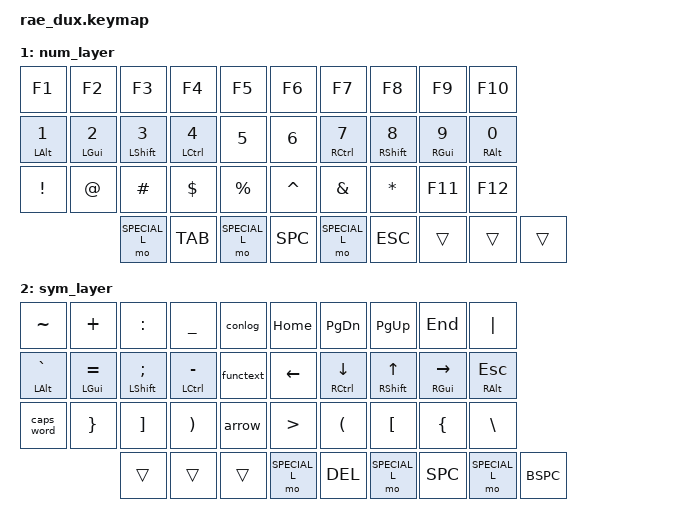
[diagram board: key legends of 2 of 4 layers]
/*
 * Copyright (c) 2021 The ZMK Contributors
 *
 * SPDX-License-Identifier: MIT
 */

#include <behaviors.dtsi>
#include <dt-bindings/zmk/bt.h>
#include <dt-bindings/zmk/keys.h>

&caps_word {
    continue-list = <UNDERSCORE MINUS BSPC>;
};

#define BASE_L  0
#define NUM_L   1
#define SYM_L   2
#define SPECIAL_L   3

&lt {
    quick-tap-ms = <200>;
};

/ {
    macros {
        ZMK_MACRO(promise, wait-ms = <30>; tap-ms = <30>; bindings = <&kp DOT &kp T &kp H &kp E &kp N &kp LPAR &kp X &kp SPC &kp EQUAL &kp GT &kp SPC &kp LBRC &kp RBRC &kp RPAR>;)
        ZMK_MACRO(anon, wait-ms = <30>; tap-ms = <30>; bindings = <&kp LPAR &kp RPAR &kp SPC &kp EQUAL &kp GT &kp SPC &kp LBRC &kp RBRC>;)
        ZMK_MACRO(arrow, wait-ms = <30>; tap-ms = <30>; bindings = <&kp EQUAL &kp GT>;)
        ZMK_MACRO(functext, wait-ms = <30>; tap-ms = <30>; bindings = <&kp F &kp U &kp N &kp C &kp T &kp I &kp O &kp N>;)
        ZMK_MACRO(conlog, wait-ms = <30>; tap-ms = <30>; bindings = <&kp C &kp O &kp N &kp S &kp O &kp L &kp E &kp DOT &kp L &kp O &kp G &kp LPAR>;)
    };

    combos {
        compatible = "zmk,combos";

        #define COMBO(NAME, BINDINGS, KEYPOS, TIMEOUT) \
              combo_##NAME { \
                timeout-ms = <TIMEOUT>; \
                bindings = <BINDINGS>; \
                key-positions = <KEYPOS>; \
              };

        /*                KEY POSITIONS

          ╭────────────────────╮ ╭────────────────────╮
          │  0   1   2   3   4 │ │  5   6   7   8   9 │
          │ 10  11  12  13  14 │ │ 15  16  17  18  19 │
          │ 20  21  22  23  24 │ │ 25  26  27  28  29 │
          ╰───────╮ 30  31  32 │ │ 33  34  35 ╭───────╯
                  ╰────────────╯ ╰────────────╯        */
        
        COMBO(caps_word_left, &caps_word, 13 14, 60)
    };

    behaviors {
        lhm: left_hand_positional_hold_tap {
            compatible = "zmk,behavior-hold-tap";
            label = "LEFT_POSITIONAL_HOLD_TAP";
            #binding-cells = <2>;
            flavor = "tap-preferred";
            tapping-term-ms = <200>;
            quick-tap-ms = <200>;
            // global-quick-tap-ms = <100>;
            bindings = <&kp>, <&kp>;
            // hold-trigger-key-positions = <5 6 7 8 9 15 16 17 18 19 25 26 27 28 29 30 31 32 33 34 35>;
            hold-trigger-key-positions = <5 6 7 8 9 10 11 12 13 15 16 17 18 19 25 26 27 28 29 30 31 32 33 34 35>;
        };

        lhctrl: left_special_hand_positional_hold_tap {
            compatible = "zmk,behavior-hold-tap";
            label = "LEFT_POSITIONAL_HOLD_TAP";
            #binding-cells = <2>;
            flavor = "tap-preferred";
            tapping-term-ms = <200>;
            quick-tap-ms = <200>;
            // global-quick-tap-ms = <100>;
            bindings = <&kp>, <&kp>;
            // hold-trigger-key-positions = <5 6 7 8 9 15 16 17 18 19 25 26 27 28 29 30 31 32 33 34 35>;
            hold-trigger-key-positions = <1 5 6 7 8 9 10 11 12 13 15 16 17 18 19 20 21 22 24 25 26 27 28 29 30 31 32 33 34 35>;
        };

        rhm: right_hand_positional_hold_tap {
            compatible = "zmk,behavior-hold-tap";
            label = "RIGHT_POSITIONAL_HOLD_TAP";
            #binding-cells = <2>;
            flavor = "tap-preferred";
            tapping-term-ms = <200>;
            quick-tap-ms = <200>;
            // global-quick-tap-ms = <100>;
            bindings = <&kp>, <&kp>;
            // hold-trigger-key-positions = <0 1 2 3 4 10 11 12 13 14 20 21 22 23 24 30 31 32 33 34 35>;
            hold-trigger-key-positions = <0 1 2 3 4 10 11 12 13 14 16 17 18 19 20 21 22 23 24 30 31 32 33 34 35>;
        };

        // base_lt: base_layer_hold_tap {
        //     compatible = "zmk,behavior-hold-tap";
        //     label = "BASE_LAYER_HOLD_TAP";
        //     #binding-cells = <2>;
        //     flavor = "tap-preferred";
        //     tapping-term-ms = <200>;
        //     quick-tap-ms = <200>;
        //     // global-quick-tap-ms = <100>;
        //     bindings = <&mo>, <&kp>;
        // };
    };

	keymap {
		compatible = "zmk,keymap";

		base_layer {
			bindings = <
                   &kp Q         &kp W         &kp F              &kp P              &kp B                &kp J              &kp L                &kp U                 &kp Y         &kp APOS
                   &lhm LALT A   &lhm LGUI R   &lhm LSHFT S       &lhctrl LCTRL T    &kp G                &kp K              &rhm LCTRL N         &rhm RSHFT E          &rhm LGUI I   &rhm RALT O
                   &kp Z         &kp X         &kp C              &kp D              &kp V                &kp M              &kp H                &kp COMMA             &kp DOT       &kp FSLH
			    	 /*&            &*/           &mo SYM_L TAB    &mo SYM_L SPC       &mo SPECIAL_L ESC      &mo SPECIAL_L DEL   &mo NUM_L RET   &mo NUM_L BSPC
			>;
		};

		num_layer {
			bindings = <
                   &kp F1           &kp F2          &kp F3          &kp F4          &kp F5              &kp F6      &kp F7          &kp F8          &kp F9          &kp F10
                   &lhm LALT N1     &lhm LGUI N2    &lhm LSHFT N3   &lhm LCTRL N4   &kp N5              &kp N6      &rhm RCTRL N7   &rhm RSHFT N8   &rhm RGUI N9    &rhm RALT N0
                   &kp EXCL         &kp AT          &kp HASH        &kp DLLR        &kp PRCNT           &kp CARET   &kp AMPS        &kp STAR        &kp F11         &kp F12
				 /*&            &*/                 &mo SPECIAL_L TAB    &mo SPECIAL_L SPC       &mo SPECIAL_L ESC              &trans      &trans          &trans
			>;
		};

		sym_layer {
			bindings = <
                   &kp TILDE           &kp PLUS             &kp COLON           &kp UNDERSCORE          &conlog                 &kp HOME          &kp PAGE_DOWN       &kp PAGE_UP      &kp END             &kp PIPE
                   &lhm LALT GRAVE     &lhm LGUI EQUAL      &lhm LSHFT SEMI     &lhm LCTRL MINUS        &functext               &kp LEFT          &rhm RCTRL DOWN     &rhm RSHFT UP    &rhm RGUI RIGHT     &rhm RALT ESC
                   &caps_word          &kp RBRC             &kp RBKT            &kp RPAR                &arrow                  &kp GT            &kp LPAR            &kp LBKT         &kp LBRC            &kp BACKSLASH
				 /*&            &*/           &trans        &trans             &trans                                           &mo SPECIAL_L DEL   &mo SPECIAL_L SPC   &mo SPECIAL_L BSPC
			>;
		};

        special_layer {
            bindings = <
                &bt BT_CLR  &trans  &trans  &promise    &trans                  &kp INS     &kp C_BRIGHTNESS_DEC    &kp C_BRIGHTNESS_INC  &kp PSCRN  &kp PAUSE_BREAK
                &anon   &trans  &trans  &caps_word  &kp CAPS                   &kp C_MUTE  &kp C_VOL_DN               &kp C_VOL_UP          &trans     &trans
                &trans  &trans  &trans  &trans      &trans                      &kp K_MUTE  &bt BT_SEL 0            &bt BT_PRV            &bt BT_NXT &trans
                                &trans  &trans      &trans                      &trans  &trans  &trans
            >;
        };
	};
};
